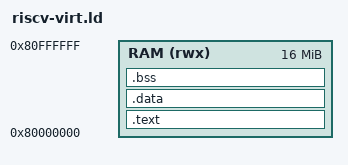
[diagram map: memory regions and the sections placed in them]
OUTPUT_ARCH(riscv)
ENTRY(_start)

/* QEMU `virt` rv32 loads the kernel ELF into DRAM at 0x80000000. */
MEMORY
{
    RAM (rwx) : ORIGIN = 0x80000000, LENGTH = 16M
}

_estack = ORIGIN(RAM) + LENGTH(RAM);

SECTIONS
{
    .text : ALIGN(4)
    {
        KEEP(*(.text.start))
        *(.text*)
        *(.rodata*)
        . = ALIGN(4);
    } > RAM

    .data : ALIGN(4)
    {
        _sdata = .;
        *(.data*)
        . = ALIGN(4);
        _edata = .;
    } > RAM
    _sidata = LOADADDR(.data);

    .bss (NOLOAD) : ALIGN(4)
    {
        _sbss = .;
        *(.bss*)
        *(COMMON)
        . = ALIGN(4);
        _ebss = .;
    } > RAM

    /DISCARD/ :
    {
        *(.comment)
        *(.note*)
        *(.eh_frame*)
    }
}
